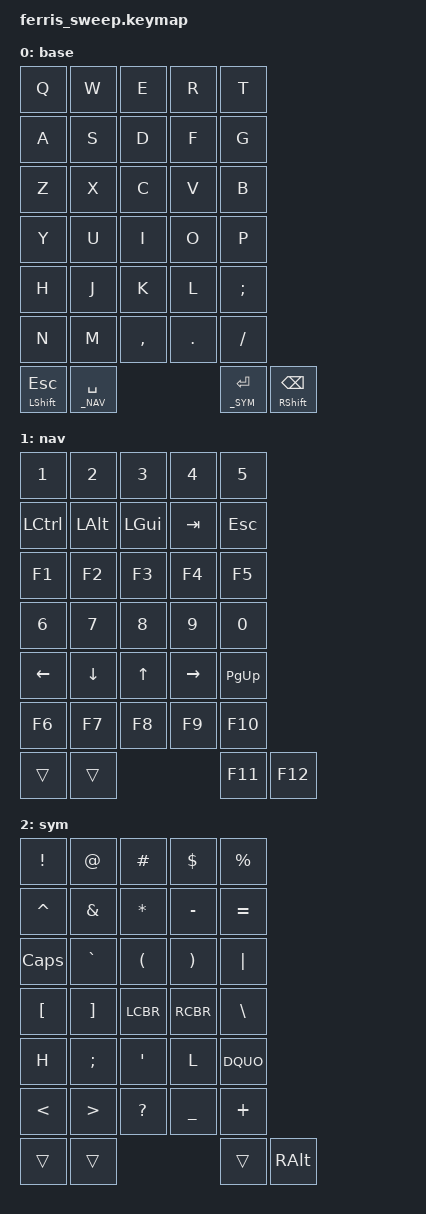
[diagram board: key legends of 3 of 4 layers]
// Ferris Sweep (3x5 + 2 thumbs per side) — ZMK keymap
// Layers: 0=BASE, 1=NAV, 2=SYM, 3=GAME
//
// Build eksempel (nice!nano v2):
//   west build -s zmk/app -b nice_nano_v2 -- -DSHIELD=sweep
//
// Tip (DK): Lad OS-layout være Dansk. Så bliver ; → Ø, ' → Æ, [ → Å.
// (Alternativt kan du bruge en locale-header fra ZMK Locale Generator.)

#include <behaviors.dtsi>
#include <dt-bindings/zmk/keys.h>
#include <dt-bindings/zmk/bt.h>

// Hvis du bruger locale-header (valgfrit):
// #include "keys_da.h"

#define _BASE 0
#define _NAV  1
#define _SYM  2
#define _GAME 3

/ {
    keymap {
        compatible = "zmk,keymap";

        // ---------------------------
        // LAYER 0 — BASE (QWERTY)
        // Tomler:
        //   L-outer:  Esc (tap) / LShift (hold)
        //   L-inner:  Space (tap) / NAV (hold)
        //   R-inner:  Enter (tap) / SYM (hold)
        //   R-outer:  Backspace (tap) / RShift (hold)
        // ---------------------------
        base {
            bindings = <
                // Left half (3x5)
                &kp Q    &kp W     &kp E      &kp R      &kp T
                &kp A    &kp S     &kp D      &kp F      &kp G
                &kp Z    &kp X     &kp C      &kp V      &kp B

                // Right half (3x5)
                &kp Y    &kp U     &kp I      &kp O      &kp P
                &kp H    &kp J     &kp K      &kp L      &kp SEMI
                &kp N    &kp M     &kp COMMA  &kp DOT    &kp SLASH

                // Thumbs: L2  L1            R1            R2
                &mt LSHFT ESC   &lt _NAV SPACE   &lt _SYM ENTER   &mt RSHFT BKSP
            >;
        };

        // -----------------------------------------
        // LAYER 1 — NAV + TALS + MODIFIERS + F-TASTER
        // Hold venstre inderste tommel (Space⇄NAV)
        // -----------------------------------------
        nav {
            bindings = <
                // Venstre top: tal 1–5
                &kp N1     &kp N2     &kp N3     &kp N4     &kp N5
                // Venstre midt: primære modifiers + Tab
                &kp LCTRL  &kp LALT   &kp LGUI   &kp TAB    &kp ESC
                // Venstre bund: F1–F5
                &kp F1     &kp F2     &kp F3     &kp F4     &kp F5

                // Højre top: tal 6–0
                &kp N6     &kp N7     &kp N8     &kp N9     &kp N0
                // Højre midt: piletaster på H J K L (+ PgUp på ; )
                &kp LEFT   &kp DOWN   &kp UP     &kp RIGHT  &kp PG_UP
                // Højre bund: F6–F10
                &kp F6     &kp F7     &kp F8     &kp F9     &kp F10

                // Tomler: (F11/F12 handy)
                &trans     &trans     &kp F11    &kp F12
            >;
        };

        // ------------------------------------------------------
        // LAYER 2 — SYMBOLER + Æ/Ø/Å + CAPS
        // Hold højre inderste tommel (Enter⇄SYM)
        //
        // DK-OS mapping:
        //   ; → Ø   ' → Æ   [ → Å
        // Lægger dem under stærke højre fingre.
        // ------------------------------------------------------
        sym {
            bindings = <
                // Venstre: operatorer
                &kp EXCL   &kp AT     &kp HASH   &kp DLLR   &kp PERCENT
                &kp CARET  &kp AMPS   &kp ASTRK  &kp MINUS  &kp EQUAL
                &kp CAPS   &kp GRAVE  &kp LPAR   &kp RPAR   &kp PIPE   // CAPS her (sikkert hjørne)

                // Højre: brackets + DK-tegn via OS
                &kp LBKT   &kp RBKT   &kp LCBR   &kp RCBR   &kp BSLH
                &kp H      &kp SEMI   &kp APOS   &kp L      &kp DQUO   // Ø (=;) og Æ (=')
                &kp LT     &kp GT     &kp QMARK  &kp UNDERSCORE &kp PLUS

                // Tomler
                &trans     &trans     &trans     &kp RALT    // AltGr hvis du får brug for den
            >;
        };

        // ------------------------------------------------------
        // LAYER 3 — GAMING (LoL)
        // Toggle via højre yderste tommel i BASE (&mt RSHFT BKSP → tap, og
        // læg evt. en dedikeret &tog _GAME på et ledigt sted hvis du vil).
        //
        // - ASDF → QWER
        // - (valgfrit) ZXCV → ASDF
        // - Ingen lag-keys for at undgå fejl i kamp
        // ------------------------------------------------------
        game {
            bindings = <
                // Venstre 3x5 (neutral)
                &trans &trans &trans &trans &trans
                &trans &trans &trans &trans &trans
                &trans &trans &trans &trans &trans

                // Højre 3x5 — midterste række: map ASDF -> QWER
                &trans &trans &kp Q  &kp W  &kp E
                &trans &trans &trans &trans &kp R
                &trans &trans &trans &trans &trans

                // Højre 3x5 — nederste række: (valgfrit) ZXCV -> ASDF
                &trans &trans &kp A  &kp S  &kp D
                &trans &trans &trans &trans &kp F
                &trans &trans &trans &trans &trans

                // Tomler: kun basale keys i spil
                &kp ESC  &kp SPACE   &kp ENTER   &tog _GAME
            >;
        };
    };
};
